# LPC1102 register map
File version: 3
Registers are 32-bit, read-write, reset 0x0 unless marked. A register's access mark holds for its fields unless they carry their own. Offsets are from the block's base; [hi:lo] are bit positions; {n}, {i} and the like mark numbered series.

## CT32B0 — Product name title=UM10429 Chapter title=LPC11102 32-bit counter/timers (CT32B0/1) Modification date=11/1/2010 Major revision=1 Minor revision=not available
Base 0x40014000
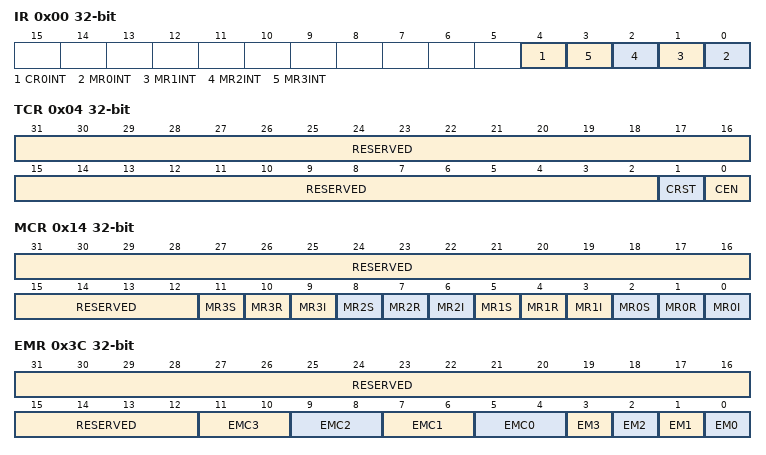
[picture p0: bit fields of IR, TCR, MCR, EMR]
0x00 IR — Interrupt Register (IR). The IR can be written to clear interrupts. The IR can be read to identify which of five possible interrupt sources are pending.
  [4] CR0INT — Interrupt flag for capture channel 0 event.
  [n] MR{n}INT (n=0..3) — Interrupt flag for match channel {n}.
0x04 TCR — Timer Control Register (TCR). The TCR is used to control the Timer Counter functions. The Timer Counter can be disabled or reset through the TCR.
  [31:2] RESERVED — Reserved, user software should not write ones to reserved bits. The value read from a reserved bit is not defined.
  [1] CRST — Counter Reset When one, the Timer Counter and the Prescale Counter are synchronously reset on the next positive edge of PCLK. The counters remain reset until TCR[1] is returned to zero.
  [0] CEN — Counter Enable When one, the Timer Counter and Prescale Counter are enabled for counting. When zero, the counters are disabled.
0x08 TC — Timer Counter (TC). The 32-bit TC is incremented every PR+1 cycles of PCLK. The TC is controlled through the TCR.
  [31:0] TC — Timer counter value.
0x0C PR — Prescale Register (PR). When the Prescale Counter (below) is equal to this value, the next clock increments the TC and clears the PC.
  [31:0] PR — Prescale counter max value.
0x10 PC — Prescale Counter (PC). The 32-bit PC is a counter which is incremented to the value stored in PR. When the value in PR is reached, the TC is incremented and the PC is cleared. The PC is observable and controllable through the bus interface.
  [31:0] PC — Prescale counter value.
0x14 MCR — Match Control Register (MCR). The MCR is used to control if an interrupt is generated and if the TC is reset when a Match occurs.
  [31:12] RESERVED — Reserved, user software should not write ones to reserved bits. The value read from a reserved bit is not defined.
  [3n+2] MR{n}S (n=0..3) — Stop on MR{n}: the TC and PC will be stopped and TCR[0] will be set to 0 if MR{n} matches the TC.
    1=Enabled; 0=Disabled
  [3n+1] MR{n}R (n=0..3) — Reset on MR{n}: the TC will be reset if MR{n} matches it.
    1=Enabled; 0=Disabled
  [3n] MR{n}I (n=0..3) — Interrupt on MR{n}: an interrupt is generated when MR{n} matches the value in the TC.
    1=Enabled; 0=Disabled
{0x18+4i} MR{i} (i=0..3) — Match Register. MR can be enabled through the MCR to reset the TC, stop both the TC and PC, and/or generate aninterrupt every time MR matches the TC.
  [31:0] MATCH — Timer counter match value.
0x3C EMR — External Match Register (EMR). The EMR controls the match function and the external match pins CT32B0_MAT[3:0].
  [31:12] RESERVED — Reserved, user software should not write ones to reserved bits. The value read from a reserved bit is not defined.
  [2n+5:2n+4] EMC{n} (n=0..3) — External Match Control {n}. Determines the functionality of External Match {n}.
    0=Do Nothing; 1=Clear the corresponding External Match bit/output to 0 (CT32Bn_MATm pin is LOW if pinned out); 2=Set the corresponding External Match bit/output to 1 (CT32Bn_MATm pin is HIGH if pinned out); 3=Toggle the corresponding External Match bit/output
  [n] EM{n} (n=0..3) — External Match {n}. This bit reflects the state of output CT32Bn_MAT{n}, whether or not this output is connected to its pin. When a match occurs between the TC and MR{n}, this bit can either toggle, go LOW, go HIGH, or do nothing. Bits EMR[{2n+5}:{2n+4}] control the functionality of this output. This bit is driven to the CT32B0_MAT{n}/CT16B1_MAT{n} pins if the match function is selected in the IOCON registers (0 = LOW, 1 = HIGH).
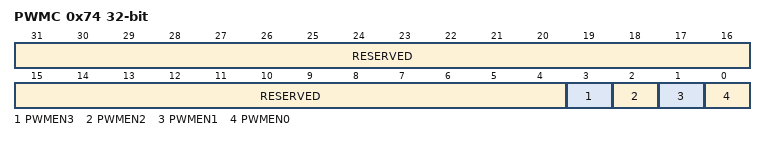
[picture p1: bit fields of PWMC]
0x74 PWMC — PWM Control Register (PWMCON). The PWMCON enables PWM mode for the external match pins CT32B0_MAT[3:0].
  [31:4] RESERVED — Reserved, user software should not write ones to reserved bits. The value read from a reserved bit is not defined.
  [3] PWMEN3 — When one, PWM mode is enabled for CT32Bn_MAT3. When zero, CT32Bn_MAT3 is controlled by EM3. Note: It is recommended to use match channel 3 to set the PWM cycle.
  [2] PWMEN2 — When one, PWM mode is enabled for CT32Bn_MAT2. When zero, CT32Bn_MAT2 is controlled by EM2.
  [1] PWMEN1 — When one, PWM mode is enabled for CT32Bn_MAT1. When zero, CT32Bn_MAT1 is controlled by EM1.
  [0] PWMEN0 — When one, PWM mode is enabled for CT32Bn_MAT0. When zero, CT32Bn_MAT0 is controlled by EM0.
